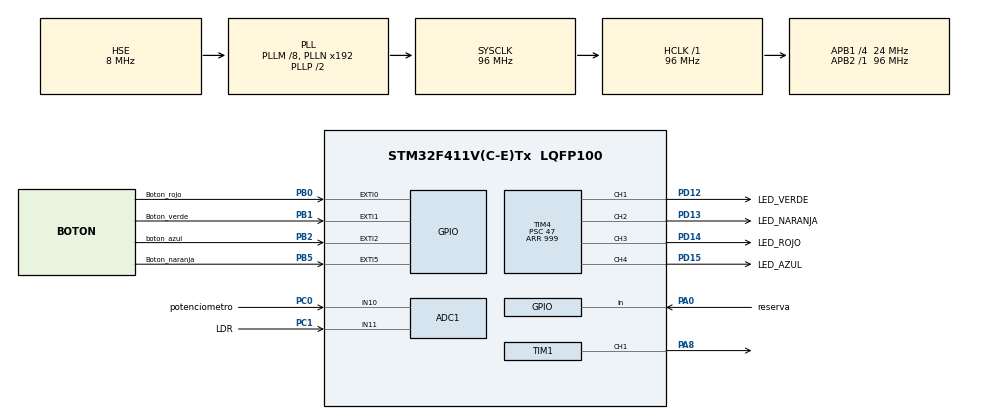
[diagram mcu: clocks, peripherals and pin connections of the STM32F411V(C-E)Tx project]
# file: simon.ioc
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ADC1.Channel-0\#ChannelRegularConversion=ADC_CHANNEL_10
ADC1.NbrOfConversionFlag=1
ADC1.Rank-0\#ChannelRegularConversion=1
ADC1.SamplingTime-0\#ChannelRegularConversion=ADC_SAMPLETIME_3CYCLES
ADC1.master=1
Mcu.Family=STM32F4
Mcu.Name=STM32F411V(C-E)Tx
Mcu.Package=LQFP100
NVIC.EXTI0_IRQn=true\:0\:0\:false\:false\:true\:true\:true\:true
NVIC.EXTI1_IRQn=true\:0\:0\:false\:false\:true\:true\:true\:true
NVIC.EXTI2_IRQn=true\:0\:0\:false\:false\:true\:true\:true\:true
NVIC.EXTI9_5_IRQn=true\:0\:0\:false\:false\:true\:true\:true\:true
NVIC.PriorityGroup=NVIC_PRIORITYGROUP_0
PA0-WKUP.GPIO_Label=reserva
PA0-WKUP.Signal=GPIO_Input
PA8.Signal=S_TIM1_CH1
PB0.GPIO_Label=Boton_rojo
PB0.GPIO_ModeDefaultEXTI=GPIO_MODE_IT_RISING
PB0.GPIO_PuPd=GPIO_PULLDOWN
PB0.Signal=GPXTI0
PB1.GPIO_Label=Boton_verde
PB1.GPIO_ModeDefaultEXTI=GPIO_MODE_IT_RISING
PB1.GPIO_PuPd=GPIO_PULLDOWN
PB1.Signal=GPXTI1
PB2.GPIO_Label=boton_azul
PB2.GPIO_ModeDefaultEXTI=GPIO_MODE_IT_RISING
PB2.GPIO_PuPd=GPIO_PULLDOWN
PB2.Signal=GPXTI2
PB5.GPIO_Label=Boton_naranja
PB5.GPIO_ModeDefaultEXTI=GPIO_MODE_IT_RISING
PB5.GPIO_PuPd=GPIO_PULLDOWN
PB5.Signal=GPXTI5
PC0.GPIO_Label=potenciometro
PC0.Signal=ADCx_IN10
PC1.GPIO_Label=LDR
PC1.Signal=ADCx_IN11
PD12.GPIO_Label=LED_VERDE
PD12.Signal=S_TIM4_CH1
PD13.GPIO_Label=LED_NARANJA
PD13.Signal=S_TIM4_CH2
PD14.GPIO_Label=LED_ROJO
PD14.Signal=S_TIM4_CH3
PD15.GPIO_Label=LED_AZUL
PD15.Signal=S_TIM4_CH4
PH0\ -\ OSC_IN.Mode=HSE-External-Oscillator
PH0\ -\ OSC_IN.Signal=RCC_OSC_IN
PH1\ -\ OSC_OUT.Mode=HSE-External-Oscillator
PH1\ -\ OSC_OUT.Signal=RCC_OSC_OUT
ProjectManager.HeapSize=0x200
ProjectManager.StackSize=0x400
ProjectManager.TargetToolchain=STM32CubeIDE
RCC.48MHZClocksFreq_Value=24000000
RCC.AHBFreq_Value=96000000
RCC.APB1CLKDivider=RCC_HCLK_DIV4
RCC.APB1Freq_Value=24000000
RCC.APB1TimFreq_Value=48000000
RCC.APB2Freq_Value=96000000
RCC.APB2TimFreq_Value=96000000
RCC.CortexFreq_Value=96000000
RCC.HCLKFreq_Value=96000000
RCC.HSE_VALUE=8000000
RCC.HSI_VALUE=16000000
RCC.LSE_VALUE=32768
RCC.PLLI2SM=5
RCC.PLLI2SN=200
RCC.PLLM=8
RCC.PLLQ=8
RCC.PLLSourceVirtual=RCC_PLLSOURCE_HSE
RCC.SYSCLKFreq_VALUE=96000000
RCC.SYSCLKSource=RCC_SYSCLKSOURCE_PLLCLK
RCC.VCOOutputFreq_Value=192000000
SH.ADCx_IN10.0=ADC1_IN10,IN10
SH.ADCx_IN11.0=ADC1_IN11,IN11
SH.S_TIM1_CH1.0=TIM1_CH1,PWM Generation1 CH1
SH.S_TIM4_CH1.0=TIM4_CH1,PWM Generation1 CH1
SH.S_TIM4_CH2.0=TIM4_CH2,PWM Generation2 CH2
SH.S_TIM4_CH3.0=TIM4_CH3,PWM Generation3 CH3
SH.S_TIM4_CH4.0=TIM4_CH4,PWM Generation4 CH4
TIM1.Channel-PWM\ Generation1\ CH1=TIM_CHANNEL_1
TIM1.Period=999
TIM1.Prescaler=95
TIM1.Pulse-PWM\ Generation1\ CH1=500
TIM4.AutoReloadPreload=TIM_AUTORELOAD_PRELOAD_ENABLE
TIM4.Channel-PWM\ Generation1\ CH1=TIM_CHANNEL_1
TIM4.Channel-PWM\ Generation2\ CH2=TIM_CHANNEL_2
TIM4.Channel-PWM\ Generation3\ CH3=TIM_CHANNEL_3
TIM4.Channel-PWM\ Generation4\ CH4=TIM_CHANNEL_4
TIM4.Period=999
TIM4.Prescaler=47
VP_TIM1_VS_ClockSourceINT.Mode=Internal
VP_TIM4_VS_ClockSourceINT.Mode=Internal
board=STM32F411E-DISCO

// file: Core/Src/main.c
/* USER CODE BEGIN Header */
/**
  ******************************************************************************
  * @file           : main.c
  * @brief          : Main program body
  ******************************************************************************
  * @attention
  *
  * Copyright (c) 2026 STMicroelectronics.
  * All rights reserved.
  *
  * This software is licensed under terms that can be found in the LICENSE file
  * in the root directory of this software component.
  * If no LICENSE file comes with this software, it is provided AS-IS.
  *
  ******************************************************************************
  */
/* USER CODE END Header */
#include "main.h"

/* USER CODE BEGIN Includes */
#include <stdlib.h>

#include "coordinator.h"
// #include "game.h"
// #include "sequence.h"
// #include "leds.h"
// #include "buttons.h"
// #include "hardware.h"
/* USER CODE END Includes */

ADC_HandleTypeDef hadc1;

TIM_HandleTypeDef htim1;
TIM_HandleTypeDef htim4;

/* USER CODE BEGIN PV */
//process variables = variables globales

/* USER CODE END PV */

void SystemClock_Config(void);
static void MX_GPIO_Init(void);
static void MX_ADC1_Init(void);
static void MX_TIM1_Init(void);
static void MX_TIM4_Init(void);

/* USER CODE BEGIN 0 */

// Puente entre las interrupciones HAL y el módulo de botones
void HAL_GPIO_EXTI_Callback(uint16_t GPIO_Pin)
{

	 Buttons_EXTI_Callback(GPIO_Pin);

}
/* USER CODE END 0 */

int main(void)
{

  /* MCU Configuration--------------------------------------------------------*/

  /* Reset of all peripherals, Initializes the Flash interface and the Systick. */
  HAL_Init();

  /* Configure the system clock */
  SystemClock_Config();

  /* Initialize all configured peripherals */
  MX_GPIO_Init();
  MX_ADC1_Init();
  MX_TIM1_Init();
  MX_TIM4_Init();
  /* USER CODE BEGIN 2 */
  ///////////////////////SIMON///////////////////////////

  // Inicializar módulo de LEDs
  // LEDs_Init();

  // Inicializar módulo de pulsadores
  // Buttons_Init();

  // Inicializar ADC y buzzer
  // Hardware_Init();

  // Inicializar semilla del generador aleatorio
  // srand(Hardware_Read_Potentiometer() ^ HAL_GetTick());

  // Inicializar juego y generar primera secuencia
  // Game_Init();
    Coordinator_Init();

  /* USER CODE END 2 */

  /* Infinite loop */
  while (1)
  {

    /* USER CODE BEGIN 3 */
	  // Game_Update();
     Coordinator_Update();
  }
  /* USER CODE END 3 */
}

void SystemClock_Config(void)
{
  RCC_OscInitTypeDef RCC_OscInitStruct = {0};
  RCC_ClkInitTypeDef RCC_ClkInitStruct = {0};

  /** Configure the main internal regulator output voltage
  */
  __HAL_RCC_PWR_CLK_ENABLE();
  __HAL_PWR_VOLTAGESCALING_CONFIG(PWR_REGULATOR_VOLTAGE_SCALE1);

  /** Initializes the RCC Oscillators according to the specified parameters
  * in the RCC_OscInitTypeDef structure.
  */
  RCC_OscInitStruct.OscillatorType = RCC_OSCILLATORTYPE_HSE;
  RCC_OscInitStruct.HSEState = RCC_HSE_ON;
  RCC_OscInitStruct.PLL.PLLState = RCC_PLL_ON;
  RCC_OscInitStruct.PLL.PLLSource = RCC_PLLSOURCE_HSE;
  RCC_OscInitStruct.PLL.PLLM = 8;
  RCC_OscInitStruct.PLL.PLLN = 192;
  RCC_OscInitStruct.PLL.PLLP = RCC_PLLP_DIV2;
  RCC_OscInitStruct.PLL.PLLQ = 8;
  if (HAL_RCC_OscConfig(&RCC_OscInitStruct) != HAL_OK)
  {
    Error_Handler();
  }

  /** Initializes the CPU, AHB and APB buses clocks
  */
  RCC_ClkInitStruct.ClockType = RCC_CLOCKTYPE_HCLK|RCC_CLOCKTYPE_SYSCLK
                              |RCC_CLOCKTYPE_PCLK1|RCC_CLOCKTYPE_PCLK2;
  RCC_ClkInitStruct.SYSCLKSource = RCC_SYSCLKSOURCE_PLLCLK;
  RCC_ClkInitStruct.AHBCLKDivider = RCC_SYSCLK_DIV1;
  RCC_ClkInitStruct.APB1CLKDivider = RCC_HCLK_DIV4;
  RCC_ClkInitStruct.APB2CLKDivider = RCC_HCLK_DIV1;

  if (HAL_RCC_ClockConfig(&RCC_ClkInitStruct, FLASH_LATENCY_3) != HAL_OK)
  {
    Error_Handler();
  }
}

static void MX_ADC1_Init(void)
{

  ADC_ChannelConfTypeDef sConfig = {0};

  /** Configure the global features of the ADC (Clock, Resolution, Data Alignment and number of conversion)
  */
  hadc1.Instance = ADC1;
  hadc1.Init.ClockPrescaler = ADC_CLOCK_SYNC_PCLK_DIV4;
  hadc1.Init.Resolution = ADC_RESOLUTION_12B;
  hadc1.Init.ScanConvMode = DISABLE;
  hadc1.Init.ContinuousConvMode = DISABLE;
  hadc1.Init.DiscontinuousConvMode = DISABLE;
  hadc1.Init.ExternalTrigConvEdge = ADC_EXTERNALTRIGCONVEDGE_NONE;
  hadc1.Init.ExternalTrigConv = ADC_SOFTWARE_START;
  hadc1.Init.DataAlign = ADC_DATAALIGN_RIGHT;
  hadc1.Init.NbrOfConversion = 1;
  hadc1.Init.DMAContinuousRequests = DISABLE;
  hadc1.Init.EOCSelection = ADC_EOC_SINGLE_CONV;
  if (HAL_ADC_Init(&hadc1) != HAL_OK)
  {
    Error_Handler();
  }

  /** Configure for the selected ADC regular channel its corresponding rank in the sequencer and its sample time.
  */
  sConfig.Channel = ADC_CHANNEL_10;
  sConfig.Rank = 1;
  sConfig.SamplingTime = ADC_SAMPLETIME_3CYCLES;
  if (HAL_ADC_ConfigChannel(&hadc1, &sConfig) != HAL_OK)
  {
    Error_Handler();
  }

}

static void MX_TIM1_Init(void)
{

  TIM_ClockConfigTypeDef sClockSourceConfig = {0};
  TIM_MasterConfigTypeDef sMasterConfig = {0};
  TIM_OC_InitTypeDef sConfigOC = {0};
  TIM_BreakDeadTimeConfigTypeDef sBreakDeadTimeConfig = {0};

  htim1.Instance = TIM1;
  htim1.Init.Prescaler = 95;
  htim1.Init.CounterMode = TIM_COUNTERMODE_UP;
  htim1.Init.Period = 999;
  htim1.Init.ClockDivision = TIM_CLOCKDIVISION_DIV1;
  htim1.Init.RepetitionCounter = 0;
  htim1.Init.AutoReloadPreload = TIM_AUTORELOAD_PRELOAD_DISABLE;
  if (HAL_TIM_Base_Init(&htim1) != HAL_OK)
  {
    Error_Handler();
  }
  sClockSourceConfig.ClockSource = TIM_CLOCKSOURCE_INTERNAL;
  if (HAL_TIM_ConfigClockSource(&htim1, &sClockSourceConfig) != HAL_OK)
  {
    Error_Handler();
  }
  if (HAL_TIM_PWM_Init(&htim1) != HAL_OK)
  {
    Error_Handler();
  }
  sMasterConfig.MasterOutputTrigger = TIM_TRGO_RESET;
  sMasterConfig.MasterSlaveMode = TIM_MASTERSLAVEMODE_DISABLE;
  if (HAL_TIMEx_MasterConfigSynchronization(&htim1, &sMasterConfig) != HAL_OK)
  {
    Error_Handler();
  }
  sConfigOC.OCMode = TIM_OCMODE_PWM1;
  sConfigOC.Pulse = 500;
  sConfigOC.OCPolarity = TIM_OCPOLARITY_HIGH;
  sConfigOC.OCNPolarity = TIM_OCNPOLARITY_HIGH;
  sConfigOC.OCFastMode = TIM_OCFAST_DISABLE;
  sConfigOC.OCIdleState = TIM_OCIDLESTATE_RESET;
  sConfigOC.OCNIdleState = TIM_OCNIDLESTATE_RESET;
  if (HAL_TIM_PWM_ConfigChannel(&htim1, &sConfigOC, TIM_CHANNEL_1) != HAL_OK)
  {
    Error_Handler();
  }
  sBreakDeadTimeConfig.OffStateRunMode = TIM_OSSR_DISABLE;
  sBreakDeadTimeConfig.OffStateIDLEMode = TIM_OSSI_DISABLE;
  sBreakDeadTimeConfig.LockLevel = TIM_LOCKLEVEL_OFF;
  sBreakDeadTimeConfig.DeadTime = 0;
  sBreakDeadTimeConfig.BreakState = TIM_BREAK_DISABLE;
  sBreakDeadTimeConfig.BreakPolarity = TIM_BREAKPOLARITY_HIGH;
  sBreakDeadTimeConfig.AutomaticOutput = TIM_AUTOMATICOUTPUT_DISABLE;
  if (HAL_TIMEx_ConfigBreakDeadTime(&htim1, &sBreakDeadTimeConfig) != HAL_OK)
  {
    Error_Handler();
  }
  HAL_TIM_MspPostInit(&htim1);

}

static void MX_TIM4_Init(void)
{

  TIM_ClockConfigTypeDef sClockSourceConfig = {0};
  TIM_MasterConfigTypeDef sMasterConfig = {0};
  TIM_OC_InitTypeDef sConfigOC = {0};

  htim4.Instance = TIM4;
  htim4.Init.Prescaler = 47;
  htim4.Init.CounterMode = TIM_COUNTERMODE_UP;
  htim4.Init.Period = 999;
  htim4.Init.ClockDivision = TIM_CLOCKDIVISION_DIV1;
  htim4.Init.AutoReloadPreload = TIM_AUTORELOAD_PRELOAD_ENABLE;
  if (HAL_TIM_Base_Init(&htim4) != HAL_OK)
  {
    Error_Handler();
  }
  sClockSourceConfig.ClockSource = TIM_CLOCKSOURCE_INTERNAL;
  if (HAL_TIM_ConfigClockSource(&htim4, &sClockSourceConfig) != HAL_OK)
  {
    Error_Handler();
  }
  if (HAL_TIM_PWM_Init(&htim4) != HAL_OK)
  {
    Error_Handler();
  }
  sMasterConfig.MasterOutputTrigger = TIM_TRGO_RESET;
  sMasterConfig.MasterSlaveMode = TIM_MASTERSLAVEMODE_DISABLE;
  if (HAL_TIMEx_MasterConfigSynchronization(&htim4, &sMasterConfig) != HAL_OK)
  {
    Error_Handler();
  }
  sConfigOC.OCMode = TIM_OCMODE_PWM1;
  sConfigOC.Pulse = 0;
  sConfigOC.OCPolarity = TIM_OCPOLARITY_HIGH;
  sConfigOC.OCFastMode = TIM_OCFAST_DISABLE;
  if (HAL_TIM_PWM_ConfigChannel(&htim4, &sConfigOC, TIM_CHANNEL_1) != HAL_OK)
  {
    Error_Handler();
  }
  if (HAL_TIM_PWM_ConfigChannel(&htim4, &sConfigOC, TIM_CHANNEL_2) != HAL_OK)
  {
    Error_Handler();
  }
  if (HAL_TIM_PWM_ConfigChannel(&htim4, &sConfigOC, TIM_CHANNEL_3) != HAL_OK)
  {
    Error_Handler();
  }
  if (HAL_TIM_PWM_ConfigChannel(&htim4, &sConfigOC, TIM_CHANNEL_4) != HAL_OK)
  {
    Error_Handler();
  }
  HAL_TIM_MspPostInit(&htim4);

}

static void MX_GPIO_Init(void)
{
  GPIO_InitTypeDef GPIO_InitStruct = {0};

  /* GPIO Ports Clock Enable */
  __HAL_RCC_GPIOH_CLK_ENABLE();
  __HAL_RCC_GPIOC_CLK_ENABLE();
  __HAL_RCC_GPIOA_CLK_ENABLE();
  __HAL_RCC_GPIOB_CLK_ENABLE();
  __HAL_RCC_GPIOD_CLK_ENABLE();

  /*Configure GPIO pin : reserva_Pin */
  GPIO_InitStruct.Pin = reserva_Pin;
  GPIO_InitStruct.Mode = GPIO_MODE_INPUT;
  GPIO_InitStruct.Pull = GPIO_NOPULL;
  HAL_GPIO_Init(reserva_GPIO_Port, &GPIO_InitStruct);

  /*Configure GPIO pins : Boton_rojo_Pin Boton_verde_Pin boton_azul_Pin Boton_naranja_Pin */
  GPIO_InitStruct.Pin = Boton_rojo_Pin|Boton_verde_Pin|boton_azul_Pin|Boton_naranja_Pin;
  GPIO_InitStruct.Mode = GPIO_MODE_IT_RISING;
  GPIO_InitStruct.Pull = GPIO_PULLDOWN;
  HAL_GPIO_Init(GPIOB, &GPIO_InitStruct);

  /* EXTI interrupt init*/
  HAL_NVIC_SetPriority(EXTI0_IRQn, 0, 0);
  HAL_NVIC_EnableIRQ(EXTI0_IRQn);

  HAL_NVIC_SetPriority(EXTI1_IRQn, 0, 0);
  HAL_NVIC_EnableIRQ(EXTI1_IRQn);

  HAL_NVIC_SetPriority(EXTI2_IRQn, 0, 0);
  HAL_NVIC_EnableIRQ(EXTI2_IRQn);

  HAL_NVIC_SetPriority(EXTI9_5_IRQn, 0, 0);
  HAL_NVIC_EnableIRQ(EXTI9_5_IRQn);

}

void Error_Handler(void)
{
  __disable_irq();
  while (1)
  {
  }
}
